# MB9AF42xK register map
File version: 1.0
Registers are 32-bit, read-write, reset 0x0 unless marked. A register's access mark holds for its fields unless they carry their own. Offsets are from the block's base; [hi:lo] are bit positions; {n}, {i} and the like mark numbered series; 'fields as' and 'values as' point back to an identical list.

## RTC — peripheral RTC
Base 0x4003B000
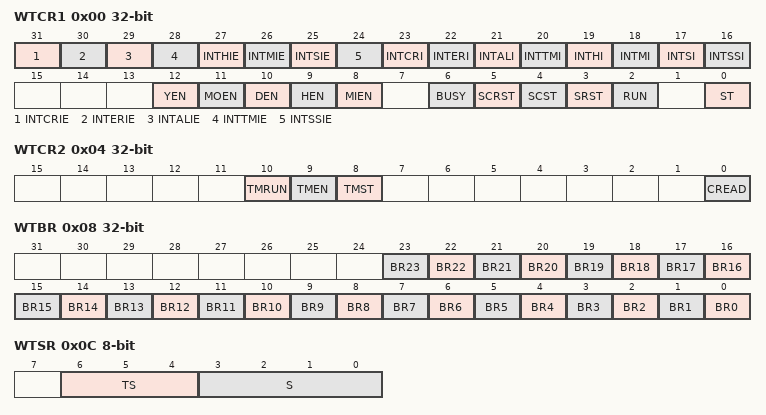
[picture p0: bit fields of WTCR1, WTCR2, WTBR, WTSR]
0x00 WTCR1
  [31] INTCRIE, [30] INTERIE, [29] INTALIE, [28] INTTMIE, [27] INTHIE, [26] INTMIE, [25] INTSIE, [24] INTSSIE, [23] INTCRI, [22] INTERI, [21] INTALI, [20] INTTMI, [19] INTHI, [18] INTMI, [17] INTSI, [16] INTSSI, [12] YEN, [11] MOEN, [10] DEN, [9] HEN, [8] MIEN, [6] BUSY ro, [5] SCRST, [4] SCST, [3] SRST, [2] RUN ro, [0] ST
0x04 WTCR2
  [10] TMRUN ro, [9] TMEN, [8] TMST, [0] CREAD
0x08 WTBR
  [n] BR{n} (n=0..23)
0x0C WTSR 8-bit
  [6:4] TS, [3:0] S
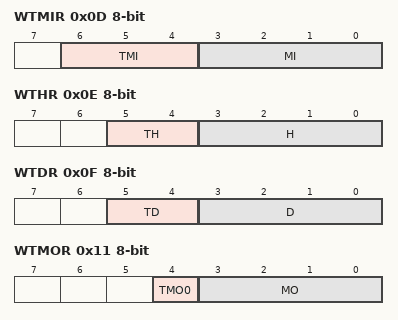
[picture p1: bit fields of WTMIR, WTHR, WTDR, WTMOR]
0x0D WTMIR 8-bit
  [6:4] TMI, [3:0] MI
0x0E WTHR 8-bit
  [5:4] TH, [3:0] H
0x0F WTDR 8-bit
  [5:4] TD, [3:0] D
0x10 WTDW 8-bit
  [2:0] DW
0x11 WTMOR 8-bit
  [4] TMO0, [3:0] MO
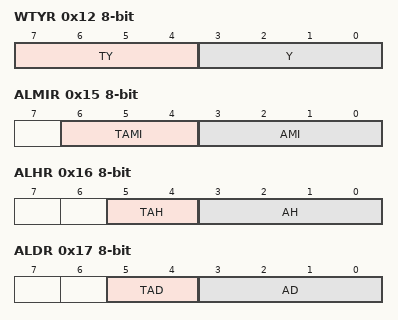
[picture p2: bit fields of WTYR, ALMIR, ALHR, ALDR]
0x12 WTYR 8-bit
  [7:4] TY, [3:0] Y
0x15 ALMIR 8-bit
  [6:4] TAMI, [3:0] AMI
0x16 ALHR 8-bit
  [5:4] TAH, [3:0] AH
0x17 ALDR 8-bit
  [5:4] TAD, [3:0] AD
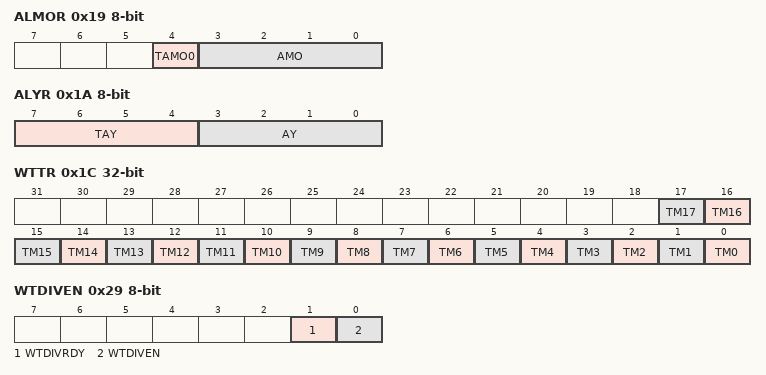
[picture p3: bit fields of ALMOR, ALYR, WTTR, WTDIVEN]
0x19 ALMOR 8-bit
  [4] TAMO0, [3:0] AMO
0x1A ALYR 8-bit
  [7:4] TAY, [3:0] AY
0x1C WTTR
  [n] TM{n} (n=0..17)
0x20 WTCLKS 8-bit
  [0] WTCLKS
0x21 WTCLKM 8-bit ro
  [1:0] WTCLKM
0x24 WTCAL 16-bit
  [9:0] WTCAL
0x26 WTCALEN 8-bit
  [0] WTCALEN
0x28 WTDIV 8-bit
  [3:0] WTDIV
0x29 WTDIVEN 8-bit
  [1] WTDIVRDY ro, [0] WTDIVEN
0x2C WTCALPRD 8-bit reset 0x13
  [5:0] WTCALPRD
0x30 WTCOSEL 8-bit
  [0] WTCOSEL

## CANPRES — peripheral CANPRES
Base 0x40037000
0x00 CANPRE 8-bit reset 0xB (reset mask 0xF)

## CAN1 — peripheral CAN1
Base 0x40063000
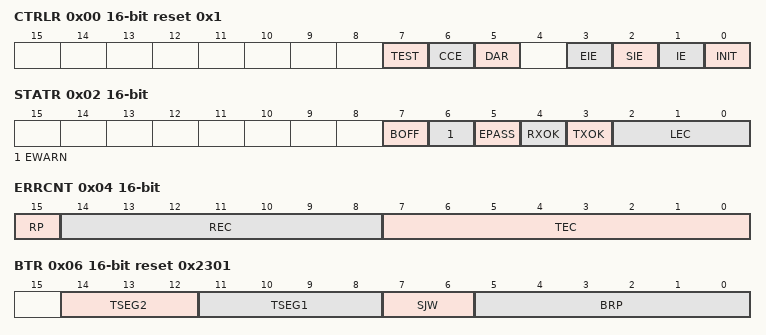
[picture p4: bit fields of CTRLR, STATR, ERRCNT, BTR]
0x00 CTRLR 16-bit reset 0x1
  [7] TEST, [6] CCE, [5] DAR, [3] EIE, [2] SIE, [1] IE, [0] INIT
0x02 STATR 16-bit
  [7] BOFF ro, [6] EWARN ro, [5] EPASS ro, [4] RXOK, [3] TXOK, [2:0] LEC
0x04 ERRCNT 16-bit ro reset not defined
  [15] RP, [14:8] REC, [7:0] TEC
0x06 BTR 16-bit reset 0x2301
  [14:12] TSEG2, [11:8] TSEG1, [7:6] SJW, [5:0] BRP
0x08 INTR 16-bit ro
  [15:0] INTID
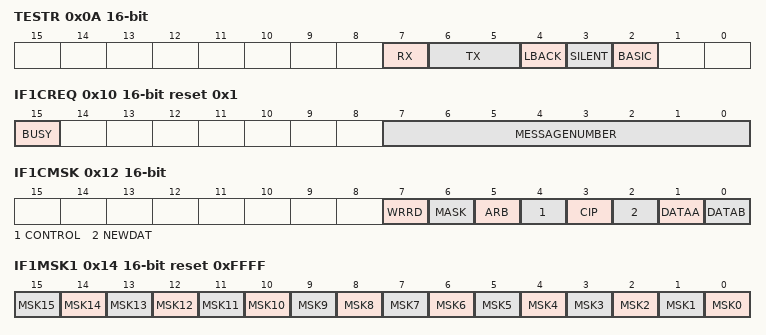
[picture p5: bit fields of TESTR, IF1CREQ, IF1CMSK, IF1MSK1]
0x0A TESTR 16-bit (reset mask 0xF4)
  [7] RX ro, [6:5] TX, [4] LBACK, [3] SILENT, [2] BASIC
0x0C BRPER 16-bit
  [3:0] BRPE
0x10 IF1CREQ 16-bit reset 0x1
  [15] BUSY, [7:0] MESSAGENUMBER
0x12 IF1CMSK 16-bit
  [7] WRRD, [6] MASK, [5] ARB, [4] CONTROL, [3] CIP, [2] NEWDAT, [1] DATAA, [0] DATAB
0x14 IF1MSK1 16-bit reset 0xFFFF
  [n] MSK{n} (n=0..15)
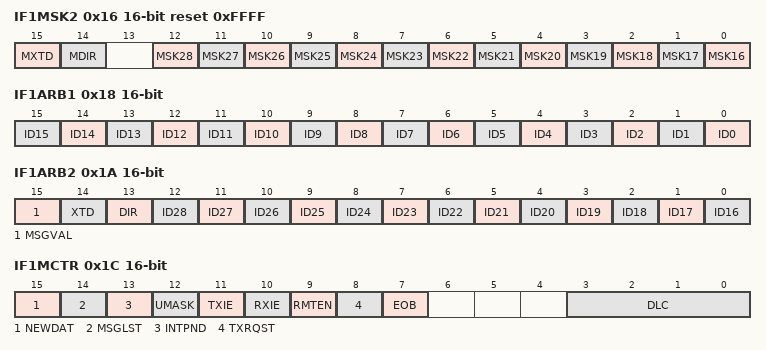
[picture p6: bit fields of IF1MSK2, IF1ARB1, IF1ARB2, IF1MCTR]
0x16 IF1MSK2 16-bit reset 0xFFFF
  [15] MXTD, [14] MDIR, [n-16] MSK{n} (n=16..28)
0x18 IF1ARB1 16-bit
  [n] ID{n} (n=0..15)
0x1A IF1ARB2 16-bit
  [15] MSGVAL, [14] XTD, [13] DIR, [n-16] ID{n} (n=16..28)
0x1C IF1MCTR 16-bit
  [15] NEWDAT, [14] MSGLST, [13] INTPND, [12] UMASK, [11] TXIE, [10] RXIE, [9] RMTEN, [8] TXRQST, [7] EOB, [3:0] DLC
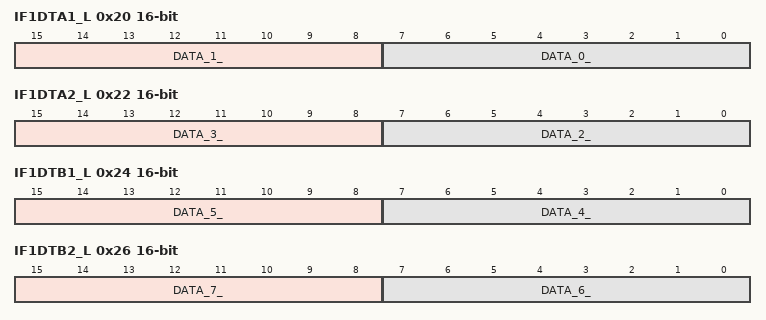
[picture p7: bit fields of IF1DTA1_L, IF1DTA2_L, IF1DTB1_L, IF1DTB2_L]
0x20 IF1DTA1_L 16-bit (reset mask 0xFF8F)
  [15:8] DATA_1_, [7:0] DATA_0_
0x22 IF1DTA2_L 16-bit
  [15:8] DATA_3_, [7:0] DATA_2_
0x24 IF1DTB1_L 16-bit
  [15:8] DATA_5_, [7:0] DATA_4_
0x26 IF1DTB2_L 16-bit
  [15:8] DATA_7_, [7:0] DATA_6_
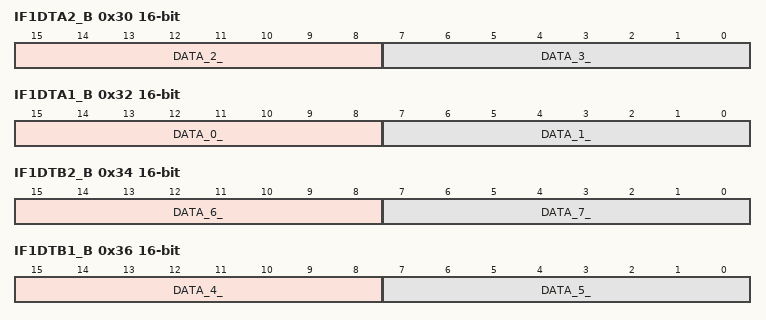
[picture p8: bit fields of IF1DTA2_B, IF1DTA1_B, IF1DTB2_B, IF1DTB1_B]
0x30 IF1DTA2_B 16-bit
  [15:8] DATA_2_, [7:0] DATA_3_
0x32 IF1DTA1_B 16-bit
  [15:8] DATA_0_, [7:0] DATA_1_
0x34 IF1DTB2_B 16-bit
  [15:8] DATA_6_, [7:0] DATA_7_
0x36 IF1DTB1_B 16-bit
  [15:8] DATA_4_, [7:0] DATA_5_
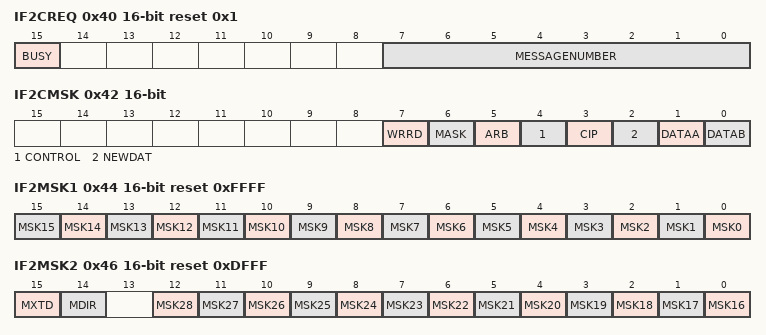
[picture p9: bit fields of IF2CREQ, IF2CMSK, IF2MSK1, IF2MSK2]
0x40 IF2CREQ 16-bit reset 0x1
  [15] BUSY, [7:0] MESSAGENUMBER
0x42 IF2CMSK 16-bit
  fields as IF1CMSK
0x44 IF2MSK1 16-bit reset 0xFFFF
  [n] MSK{n} (n=0..15)
0x46 IF2MSK2 16-bit reset 0xDFFF
  [15] MXTD, [14] MDIR, [n-16] MSK{n} (n=16..28)
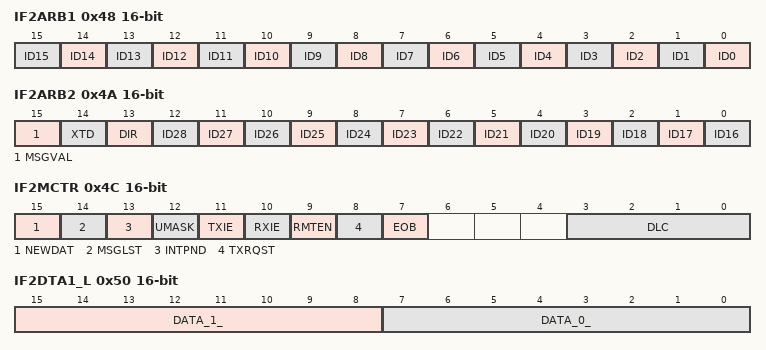
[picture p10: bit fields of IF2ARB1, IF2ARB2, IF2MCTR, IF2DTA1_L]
0x48 IF2ARB1 16-bit
  [n] ID{n} (n=0..15)
0x4A IF2ARB2 16-bit
  [15] MSGVAL, [14] XTD, [13] DIR, [n-16] ID{n} (n=16..28)
0x4C IF2MCTR 16-bit
  fields as IF1MCTR
0x50 IF2DTA1_L 16-bit
  [15:8] DATA_1_, [7:0] DATA_0_
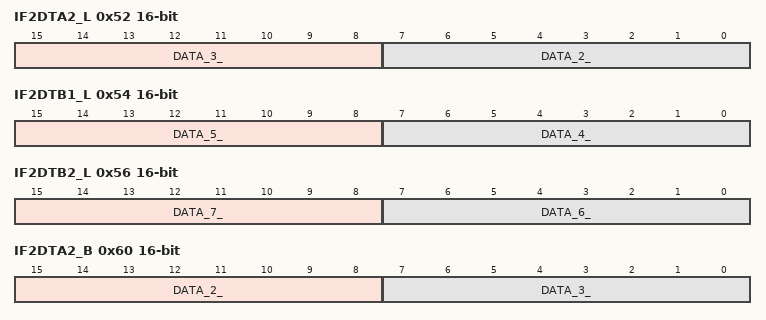
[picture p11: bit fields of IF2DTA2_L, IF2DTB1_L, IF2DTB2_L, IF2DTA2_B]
0x52 IF2DTA2_L 16-bit
  [15:8] DATA_3_, [7:0] DATA_2_
0x54 IF2DTB1_L 16-bit
  [15:8] DATA_5_, [7:0] DATA_4_
0x56 IF2DTB2_L 16-bit
  [15:8] DATA_7_, [7:0] DATA_6_
0x60 IF2DTA2_B 16-bit
  [15:8] DATA_2_, [7:0] DATA_3_
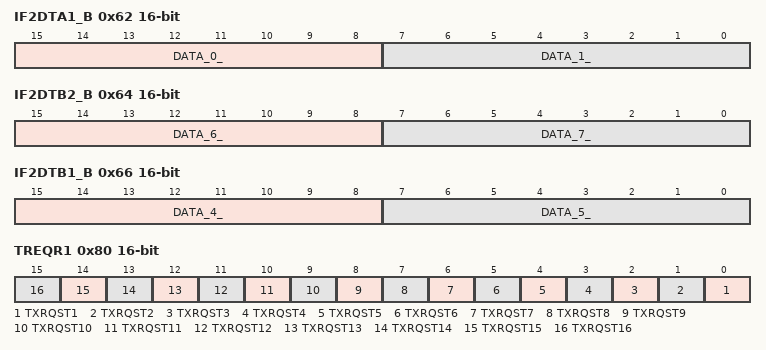
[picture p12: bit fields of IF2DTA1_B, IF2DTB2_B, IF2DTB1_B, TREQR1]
0x62 IF2DTA1_B 16-bit
  [15:8] DATA_0_, [7:0] DATA_1_
0x64 IF2DTB2_B 16-bit
  [15:8] DATA_6_, [7:0] DATA_7_
0x66 IF2DTB1_B 16-bit
  [15:8] DATA_4_, [7:0] DATA_5_
0x80 TREQR1 16-bit ro
  [n-1] TXRQST{n} (n=1..16)
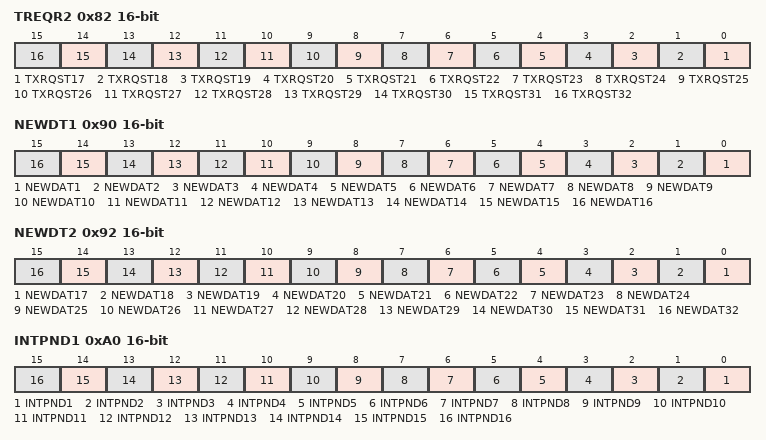
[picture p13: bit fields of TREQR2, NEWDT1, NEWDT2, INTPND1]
0x82 TREQR2 16-bit ro
  [n-17] TXRQST{n} (n=17..32)
0x90 NEWDT1 16-bit ro
  [n-1] NEWDAT{n} (n=1..16)
0x92 NEWDT2 16-bit ro
  [n-17] NEWDAT{n} (n=17..32)
0xA0 INTPND1 16-bit ro
  [n-1] INTPND{n} (n=1..16)
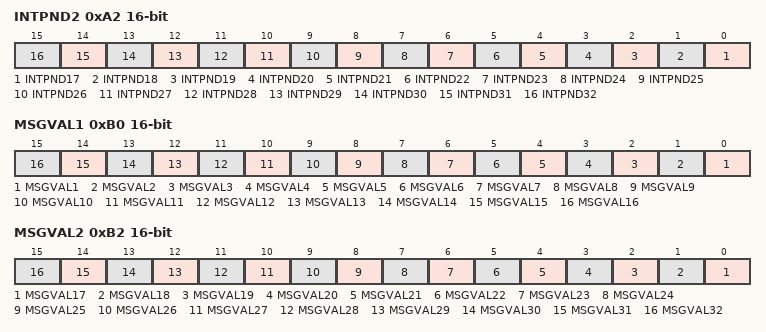
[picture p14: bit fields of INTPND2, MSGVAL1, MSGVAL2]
0xA2 INTPND2 16-bit ro
  [n-17] INTPND{n} (n=17..32)
0xB0 MSGVAL1 16-bit ro
  [n-1] MSGVAL{n} (n=1..16)
0xB2 MSGVAL2 16-bit ro
  [n-17] MSGVAL{n} (n=17..32)
